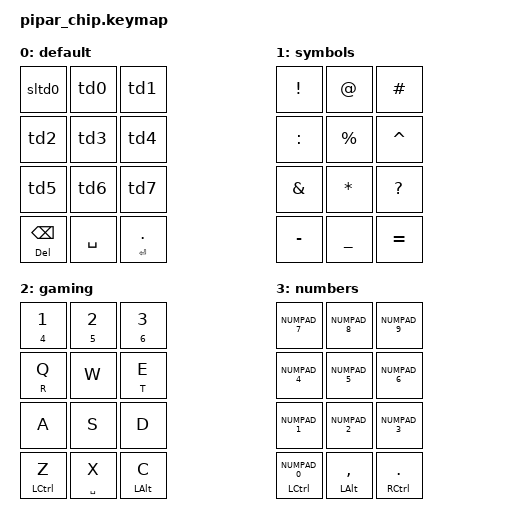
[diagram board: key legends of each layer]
/*
 * Copyright (c) 2025 The ZMK Contributors
 *
 * SPDX-License-Identifier: MIT
 */

#include <behaviors.dtsi>
#include <dt-bindings/zmk/keys.h>
#include <dt-bindings/zmk/bt.h>
#include <dt-bindings/zmk/outputs.h>


#define AS(keycode) &as LS(keycode) keycode     // Autoshift Macro

#define BASE  0
#define LSYMBOLS 1
#define GAMING 2
#define NUMBERS 3


/ {
  behaviors {

    slt: sticky_layer_tap {
      compatible = "zmk,behavior-hold-tap";
      #binding-cells = <2>;
      flavor = "tap-preferred";
      tapping-term-ms = <300>;
      bindings = <&sl>, <&kp>;
      display-name = "Sticky-Layer-Tap";
    };

    sltd0: sticky_layer_tap_dance {
      compatible = "zmk,behavior-tap-dance";
      #binding-cells = <0>;
      tapping-term-ms = <300>;
      bindings = <&slt LSYMBOLS DOT>, <&kp COMMA>, <&kp QUESTION>, <&kp EXCLAMATION>;
    };

    td0: tap_dance0 {
      compatible = "zmk,behavior-tap-dance";
      #binding-cells = <0>;
      tapping-term-ms = <300>;
      bindings = <&mt UP A>, <&kp B>, <&kp C>;
    };

    td1: tap_dance1 {
      compatible = "zmk,behavior-tap-dance";
      #binding-cells = <0>;
      tapping-term-ms = <300>;
      bindings = <&kp D>, <&kp E>, <&kp F>;
    };

    td2: tap_dance2 {
      compatible = "zmk,behavior-tap-dance";
      #binding-cells = <0>;
      tapping-term-ms = <300>;
      bindings = <&mt LEFT G>, <&kp H>, <&kp I>;
    };

    td3: tap_dance3 {
      compatible = "zmk,behavior-tap-dance";
      #binding-cells = <0>;
      tapping-term-ms = <300>;
      bindings = <&mt DOWN J>, <&kp K>, <&kp L>;
    };

    td4: tap_dance4 {
      compatible = "zmk,behavior-tap-dance";
      #binding-cells = <0>;
      tapping-term-ms = <300>;
      bindings = <&mt RIGHT M>, <&kp N>, <&kp O>;
    };

    td5: tap_dance5 {
      compatible = "zmk,behavior-tap-dance";
      #binding-cells = <0>;
      tapping-term-ms = <300>;
      bindings = <&kp P>, <&kp Q>, <&kp R>, <&kp S>;
    };

    td6: tap_dance6 {
      compatible = "zmk,behavior-tap-dance";
      #binding-cells = <0>;
      tapping-term-ms = <300>;
      bindings = <&mt TAB T>, <&kp U>, <&kp V>;
    };

    td7: tap_dance7 {
      compatible = "zmk,behavior-tap-dance";
      #binding-cells = <0>;
      tapping-term-ms = <300>;
      bindings = <&kp W>, <&kp X>, <&kp Y>, <&kp Z>;
    };
  };

  combos {
    compatible = "zmk,combos";
    combo_gaming {
      timeout-ms = <50>;
      key-positions = <9 10 11>;
      bindings = <&to GAMING>;
      require-prior-idle-ms = <300>;
      layers = <BASE>;
    };

    combo_symbols {
      timeout-ms = <50>;
      key-positions = <6 7 8>;
      bindings = <&to LSYMBOLS>;
      require-prior-idle-ms = <300>;
      layers = <BASE>;
    };

    combo_numbers {
      timeout-ms = <50>;
      key-positions = <3 4 5>;
      bindings = <&to NUMBERS>;
      require-prior-idle-ms = <300>;
      layers = <BASE>;
    };

    combo_base {
      timeout-ms = <50>;
      key-positions = <9 10 11>;
      bindings = <&to BASE>;
      require-prior-idle-ms = <300>;
      layers = <LSYMBOLS GAMING NUMBERS>;
    };

    combo_bt_clr_all {
      timeout-ms = <50>;
      key-positions = <0 1 2>;
      bindings = <&bt BT_CLR_ALL>;
      require-prior-idle-ms = <300>;
      layers = <LSYMBOLS>;
    };

    combo_bt_prev {
      timeout-ms = <50>;
      key-positions = <0 1>;
      bindings = <&bt BT_PRV>;
      require-prior-idle-ms = <300>;
      layers = <LSYMBOLS>;
    };

    combo_bt_next {
      timeout-ms = <50>;
      key-positions = <1 2>;
      bindings = <&bt BT_NXT>;
      require-prior-idle-ms = <300>;
      layers = <LSYMBOLS>;
    };

    combo_bt_tog {
      timeout-ms = <50>;
      key-positions = <0 2>;
      bindings = <&out OUT_TOG>;
      require-prior-idle-ms = <300>;
      layers = <LSYMBOLS>;
    };

  };

  keymap {
    compatible = "zmk,keymap";

    default_layer {
        display-name = "default";
        bindings = <
          &sltd0                &td0                &td1
          &td2                  &td3                &td4
          &td5                  &td6                &td7
          &mt DELETE BACKSPACE  &kp SPACE &mt ENTER DOT
        >;
    };

    symbols_layer {
      display-name = "symbols";
      bindings = <
        &kp EXCLAMATION &kp AT          &kp HASH
        &kp COLON       &kp PERCENT     &kp CARET
        &kp AMPERSAND   &kp ASTERISK    &kp QUESTION
        &kp MINUS       &kp UNDERSCORE  &kp EQUAL
      >;
    };

    gaming_layer {
      display-name = "gaming";
      bindings = <
        &mt NUMBER_4 NUMBER_1 &mt NUMBER_5 NUMBER_2 &mt NUMBER_6 NUMBER_3
        &mt R Q               &kp W                 &mt T E
        &kp A                 &kp S                 &kp D
        &mt LCTRL Z           &mt SPACE X           &mt LALT C
      >;
    };

    numbers_layer {
      display-name = "numbers";
      bindings = <
        &kp NUMPAD_7        &kp NUMPAD_8      &kp NUMPAD_9
        &kp NUMPAD_4        &kp NUMPAD_5      &kp NUMPAD_6
        &kp NUMPAD_1        &kp NUMPAD_2      &kp NUMPAD_3
        &mt LCTRL NUMPAD_0  &mt LALT COMMA    &mt RCTRL PERIOD
      >;
    };
  };
};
